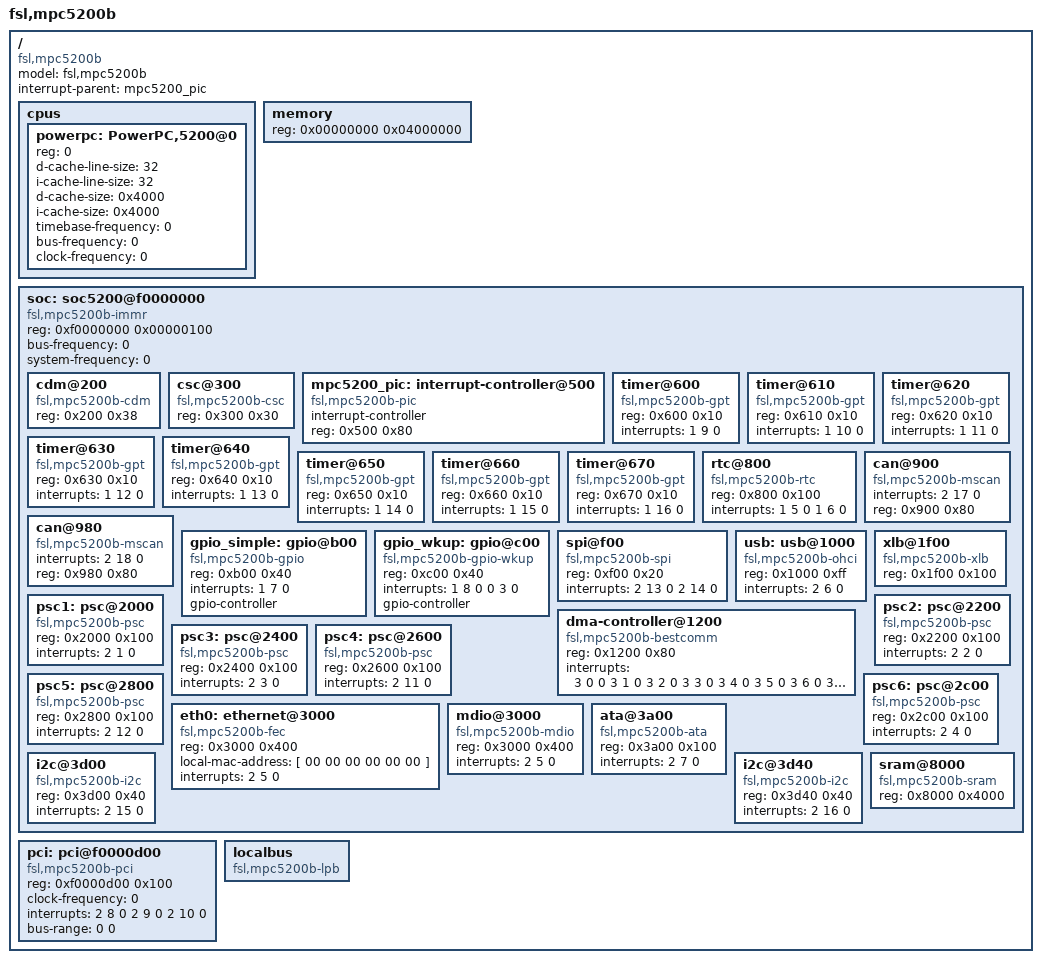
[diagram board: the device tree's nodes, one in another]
/*
 * base MPC5200b Device Tree Source
 *
 * Copyright (C) 2010 SecretLab
 * Grant Likely <grant@secretlab.ca>
 * John Bonesio <bones@secretlab.ca>
 *
 * Urs Graf <urs.graf@ntb.ch>, 2014
 *
 * This program is free software; you can redistribute  it and/or modify it
 * under  the terms of  the GNU General  Public License as published by the
 * Free Software Foundation;  either version 2 of the  License, or (at your
 * option) any later version.
 */

/dts-v1/;

/ {							// root node
	model = "fsl,mpc5200b";				// manufacturer (freescale), model
	compatible = "fsl,mpc5200b";			// name of the system
	#address-cells = <1>;				// nof addr in reg tuples of child nodes
	#size-cells = <1>;				// nof size in reg tuples of child nodes
	interrupt-parent = <&mpc5200_pic>;

	cpus {						// container for cpus
		#address-cells = <1>;			// a cpu has a single unique id 
		#size-cells = <0>;			// .. and no size

		powerpc: PowerPC,5200@0 {		// id = 0
			device_type = "cpu";
			reg = <0>;			// id = 0
			d-cache-line-size = <32>;
			i-cache-line-size = <32>;
			d-cache-size = <0x4000>;	// L1, 16K
			i-cache-size = <0x4000>;	// L1, 16K
			timebase-frequency = <0>;	// from bootloader
			bus-frequency = <0>;		// from bootloader
			clock-frequency = <0>;		// from bootloader
		};
	};

	memory: memory {
		device_type = "memory";
		reg = <0x00000000 0x04000000>;		// 64MB
	};

	soc: soc5200@f0000000 {				// container for all peripheral devices at absolute addr 0xf000'0000
		#address-cells = <1>;			// nof addr in reg tuples of child nodes
		#size-cells = <1>;			// nof size in reg tuples of child nodes
		compatible = "fsl,mpc5200b-immr";
		ranges = <0 0xf0000000 0x0000c000>;	// soc has rel. addr=0 with size=0c000 at absolute addr 0xf000'0000
		reg = <0xf0000000 0x00000100>;		// device node soc resides at addr 0xf000'0000 with size=0x100 of the parent node (=root), this is the Memory Map Register space
		bus-frequency = <0>;			// from bootloader
		system-frequency = <0>;			// from bootloader

		cdm@200 {				// clock distribution device node at rel. addr 0x200
			compatible = "fsl,mpc5200b-cdm","fsl,mpc5200-cdm";	// tells, which device driver to bind
			reg = <0x200 0x38>;		// resides at addr 0x200 with size=0x38 of the parent node (=soc)
		};

		csc@300 {				// chip select controller at rel. addr 0x300
			compatible = "fsl,mpc5200b-csc","fsl,mpc5200-csc";	// tells, which device driver to bind
			reg = <0x300 0x30>;		// resides at addr 0x300 with size=0x30 of the parent node (=soc)
		};

		mpc5200_pic: interrupt-controller@500 {	// int controller device node at rel. addr 0x500
			// 5200 interrupts are encoded into two levels;
			interrupt-controller;
			#interrupt-cells = <3>;
			compatible = "fsl,mpc5200b-pic","fsl,mpc5200-pic";	// tells, which device driver to bind
			reg = <0x500 0x80>;		// resides at addr 0x500 with size=0x80 of the parent node (=soc)
		};

		timer@600 {				// General Purpose Timer
			compatible = "fsl,mpc5200b-gpt","fsl,mpc5200-gpt";
			reg = <0x600 0x10>;
			interrupts = <1 9 0>;
		};

		timer@610 {				// General Purpose Timer
			compatible = "fsl,mpc5200b-gpt","fsl,mpc5200-gpt";
			reg = <0x610 0x10>;
			interrupts = <1 10 0>;
		};

		timer@620 {				// General Purpose Timer
			compatible = "fsl,mpc5200b-gpt","fsl,mpc5200-gpt";
			reg = <0x620 0x10>;
			interrupts = <1 11 0>;
		};

		timer@630 {				// General Purpose Timer
			compatible = "fsl,mpc5200b-gpt","fsl,mpc5200-gpt";
			reg = <0x630 0x10>;
			interrupts = <1 12 0>;
		};

		timer@640 {				// General Purpose Timer
			compatible = "fsl,mpc5200b-gpt","fsl,mpc5200-gpt";
			reg = <0x640 0x10>;
			interrupts = <1 13 0>;
		};

		timer@650 {				// General Purpose Timer
			compatible = "fsl,mpc5200b-gpt","fsl,mpc5200-gpt";
			reg = <0x650 0x10>;
			interrupts = <1 14 0>;
		};

		timer@660 {				// General Purpose Timer
			compatible = "fsl,mpc5200b-gpt","fsl,mpc5200-gpt";
			reg = <0x660 0x10>;
			interrupts = <1 15 0>;
		};

		timer@670 {				// General Purpose Timer
			compatible = "fsl,mpc5200b-gpt","fsl,mpc5200-gpt";
			reg = <0x670 0x10>;
			interrupts = <1 16 0>;
		};

		rtc@800 {				// Real time clock
			compatible = "fsl,mpc5200b-rtc","fsl,mpc5200-rtc";
			reg = <0x800 0x100>;
			interrupts = <1 5 0 1 6 0>;
		};

		can@900 {
			compatible = "fsl,mpc5200b-mscan","fsl,mpc5200-mscan";
			interrupts = <2 17 0>;
			reg = <0x900 0x80>;
		};

		can@980 {
			compatible = "fsl,mpc5200b-mscan","fsl,mpc5200-mscan";
			interrupts = <2 18 0>;
			reg = <0x980 0x80>;
		};

		gpio_simple: gpio@b00 {
			compatible = "fsl,mpc5200b-gpio","fsl,mpc5200-gpio";
			reg = <0xb00 0x40>;
			interrupts = <1 7 0>;
			gpio-controller;
			#gpio-cells = <2>;
		};

		gpio_wkup: gpio@c00 {
			compatible = "fsl,mpc5200b-gpio-wkup","fsl,mpc5200-gpio-wkup";
			reg = <0xc00 0x40>;
			interrupts = <1 8 0 0 3 0>;
			gpio-controller;
			#gpio-cells = <2>;
		};

		spi@f00 {				// spi device node at rel. addr 0xf00		
			#address-cells = <1>;		// children of this node will have single addresses
			#size-cells = <0>;		// .. and no size
			compatible = "fsl,mpc5200b-spi","fsl,mpc5200-spi";
			reg = <0xf00 0x20>;		// device node spi resides at addr 0xf00 with size=0x20 of the parent node (=soc)
			interrupts = <2 13 0 2 14 0>;
		};

		usb: usb@1000 {
			compatible = "fsl,mpc5200b-ohci","fsl,mpc5200-ohci","ohci-be";
			reg = <0x1000 0xff>;
			interrupts = <2 6 0>;
		};

		dma-controller@1200 {
			compatible = "fsl,mpc5200b-bestcomm","fsl,mpc5200-bestcomm";
			reg = <0x1200 0x80>;
			interrupts = <3 0 0  3 1 0  3 2 0  3 3 0
			              3 4 0  3 5 0  3 6 0  3 7 0
			              3 8 0  3 9 0  3 10 0  3 11 0
			              3 12 0  3 13 0  3 14 0  3 15 0>;
		};

		xlb@1f00 {
			compatible = "fsl,mpc5200b-xlb","fsl,mpc5200-xlb";
			reg = <0x1f00 0x100>;
		};

		psc1: psc@2000 {			// PSC1
			compatible = "fsl,mpc5200b-psc","fsl,mpc5200-psc";
			reg = <0x2000 0x100>;
			interrupts = <2 1 0>;
		};

		psc2: psc@2200 {			// PSC2
			compatible = "fsl,mpc5200b-psc","fsl,mpc5200-psc";
			reg = <0x2200 0x100>;
			interrupts = <2 2 0>;
		};

		psc3: psc@2400 {			// PSC3
			compatible = "fsl,mpc5200b-psc","fsl,mpc5200-psc";
			reg = <0x2400 0x100>;
			interrupts = <2 3 0>;
		};

		psc4: psc@2600 {			// PSC4
			compatible = "fsl,mpc5200b-psc","fsl,mpc5200-psc";
			reg = <0x2600 0x100>;
			interrupts = <2 11 0>;
		};

		psc5: psc@2800 {			// PSC5
			compatible = "fsl,mpc5200b-psc","fsl,mpc5200-psc";
			reg = <0x2800 0x100>;
			interrupts = <2 12 0>;
		};

		psc6: psc@2c00 {			// PSC6
			compatible = "fsl,mpc5200b-psc","fsl,mpc5200-psc";
			reg = <0x2c00 0x100>;
			interrupts = <2 4 0>;
		};

		eth0: ethernet@3000 {
			compatible = "fsl,mpc5200b-fec","fsl,mpc5200-fec";
			reg = <0x3000 0x400>;
			local-mac-address = [ 00 00 00 00 00 00 ];
			interrupts = <2 5 0>;
		};

		mdio@3000 {				
			#address-cells = <1>;		// children of this node will have single addresses
			#size-cells = <0>;		// .. and no size
			compatible = "fsl,mpc5200b-mdio","fsl,mpc5200-mdio";
			reg = <0x3000 0x400>;		// fec range, since we need to setup fec interrupts
			interrupts = <2 5 0>;		// these are for "mii command finished", not link changes & co.
		};

		ata@3a00 {
			compatible = "fsl,mpc5200b-ata","fsl,mpc5200-ata";
			reg = <0x3a00 0x100>;
			interrupts = <2 7 0>;
		};

		i2c@3d00 {
			#address-cells = <1>;		// children of this node will have single addresses
			#size-cells = <0>;		// .. and no size
			compatible = "fsl,mpc5200b-i2c","fsl,mpc5200-i2c","fsl-i2c";
			reg = <0x3d00 0x40>;
			interrupts = <2 15 0>;
		};

		i2c@3d40 {
			#address-cells = <1>;		// children of this node will have single addresses
			#size-cells = <0>;		// .. and no size
			compatible = "fsl,mpc5200b-i2c","fsl,mpc5200-i2c","fsl-i2c";
			reg = <0x3d40 0x40>;
			interrupts = <2 16 0>;
		};

		sram@8000 {				// device node for internal ram
			compatible = "fsl,mpc5200b-sram","fsl,mpc5200-sram";
			reg = <0x8000 0x4000>;		// device node sram resides at addr 0x8000 with size=16k of the parent node (=soc)
		};
	};

	pci: pci@f0000d00 {
		#interrupt-cells = <1>;
		#size-cells = <2>;			// child nodes of pci will have 2 size fields
		#address-cells = <3>;			// child nodes of pci will have 3 addr fields
		device_type = "pci";
		compatible = "fsl,mpc5200b-pci","fsl,mpc5200-pci";
		reg = <0xf0000d00 0x100>;		// device node pci resides at addr 0xf000'0d00 with size=0x100 of the parent node (=root)
		// interrupt-map-mask = need to add
		// interrupt-map = need to add
		clock-frequency = <0>; // From boot loader
		interrupts = <2 8 0 2 9 0 2 10 0>;
		bus-range = <0 0>;
		// ranges = need to add
	};

	localbus: localbus {
		compatible = "fsl,mpc5200b-lpb","fsl,mpc5200-lpb","simple-bus";
		#address-cells = <2>;			// child nodes of localbus will have 2 addr fields
		#size-cells = <1>;			// child nodes of localbus will have 1 size field
		ranges = <0 0 0xfc000000 0x2000000>;	// device node localbus has a range with relative addr. of 0 and resides at addr 0xfc00'0000 with size=0x2000000 of the parent node (=root), the first 0 indicates that CS0 is used
	};
};
